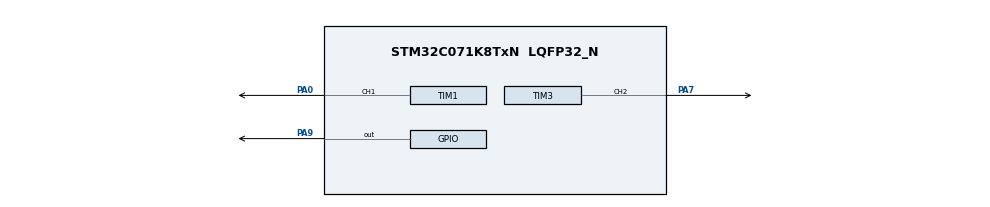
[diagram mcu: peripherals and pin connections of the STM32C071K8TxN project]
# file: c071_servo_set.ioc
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Mcu.Family=STM32C0
Mcu.Name=STM32C071K8TxN
Mcu.Package=LQFP32_N
PA0.Signal=S_TIM1_CH1
PA7.Signal=S_TIM3_CH2
PA9.PinState=GPIO_PIN_SET
PA9.Signal=GPIO_Output
ProjectManager.HeapSize=0x200
ProjectManager.StackSize=0x400
ProjectManager.TargetToolchain=STM32CubeIDE
RCC.ADCFreq_Value=48000000
RCC.AHBFreq_Value=48000000
RCC.CortexFreq_Value=48000000
RCC.EXTERNAL_CLOCK_VALUE=12288000
RCC.HCLKFreq_Value=48000000
RCC.HSE_VALUE=8000000
RCC.HSI48_VALUE=48000000
RCC.HSISYSCLKDivider=RCC_HSI_DIV1
RCC.HSI_VALUE=48000000
RCC.LSE_VALUE=32768
RCC.SYSCLKFreq_VALUE=48000000
SH.S_TIM1_CH1.0=TIM1_CH1,PWM Generation1 CH1
SH.S_TIM3_CH2.0=TIM3_CH2,PWM Generation2 CH2
TIM1.Channel-PWM\ Generation1\ CH1=TIM_CHANNEL_1
TIM3.Channel-PWM\ Generation2\ CH2=TIM_CHANNEL_2
TIM3.Prescaler=48
VP_TIM2_VS_ClockSourceINT.Mode=Internal
VP_TIM3_VS_ClockSourceINT.Mode=Internal
board=custom

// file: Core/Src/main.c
/* USER CODE BEGIN Header */
/**
  ******************************************************************************
  * @file           : main.c
  * @brief          : Main program body
  ******************************************************************************
  * @attention
  *
  * Copyright (c) 2026 STMicroelectronics.
  * All rights reserved.
  *
  * This software is licensed under terms that can be found in the LICENSE file
  * in the root directory of this software component.
  * If no LICENSE file comes with this software, it is provided AS-IS.
  *
  ******************************************************************************
  */
/* USER CODE END Header */
#include "main.h"

TIM_HandleTypeDef htim1;
TIM_HandleTypeDef htim2;
TIM_HandleTypeDef htim3;

void SystemClock_Config(void);
static void MX_GPIO_Init(void);
static void MX_TIM1_Init(void);
static void MX_TIM2_Init(void);
static void MX_TIM3_Init(void);

int main(void)
{

  /* MCU Configuration--------------------------------------------------------*/

  /* Reset of all peripherals, Initializes the Flash interface and the Systick. */
  HAL_Init();

  /* Configure the system clock */
  SystemClock_Config();

  /* Initialize all configured peripherals */
  MX_GPIO_Init();
  MX_TIM1_Init();
  MX_TIM2_Init();
  MX_TIM3_Init();
  /* USER CODE BEGIN 2 */
  HAL_TIM_Base_Start(&htim3);

  HAL_TIM_PWM_Start(&htim3, TIM_CHANNEL_2);

  HAL_Delay(100);
  /* USER CODE END 2 */

  /* Infinite loop */
  /* USER CODE BEGIN WHILE */
  while (1)
  {
// git commit attempt
	  servo_set_angle(0);
	  HAL_Delay(2000);
	  servo_set_angle(180);
	  HAL_Delay(2000);

    /* USER CODE END WHILE */

  }
}

void SystemClock_Config(void)
{
  RCC_OscInitTypeDef RCC_OscInitStruct = {0};
  RCC_ClkInitTypeDef RCC_ClkInitStruct = {0};

  __HAL_FLASH_SET_LATENCY(FLASH_LATENCY_1);

  /** Initializes the RCC Oscillators according to the specified parameters
  * in the RCC_OscInitTypeDef structure.
  */
  RCC_OscInitStruct.OscillatorType = RCC_OSCILLATORTYPE_HSI;
  RCC_OscInitStruct.HSIState = RCC_HSI_ON;
  RCC_OscInitStruct.HSIDiv = RCC_HSI_DIV1;
  RCC_OscInitStruct.HSICalibrationValue = RCC_HSICALIBRATION_DEFAULT;
  if (HAL_RCC_OscConfig(&RCC_OscInitStruct) != HAL_OK)
  {
    Error_Handler();
  }

  /** Initializes the CPU, AHB and APB buses clocks
  */
  RCC_ClkInitStruct.ClockType = RCC_CLOCKTYPE_HCLK|RCC_CLOCKTYPE_SYSCLK
                              |RCC_CLOCKTYPE_PCLK1;
  RCC_ClkInitStruct.SYSCLKSource = RCC_SYSCLKSOURCE_HSI;
  RCC_ClkInitStruct.SYSCLKDivider = RCC_SYSCLK_DIV1;
  RCC_ClkInitStruct.AHBCLKDivider = RCC_HCLK_DIV1;
  RCC_ClkInitStruct.APB1CLKDivider = RCC_APB1_DIV1;

  if (HAL_RCC_ClockConfig(&RCC_ClkInitStruct, FLASH_LATENCY_1) != HAL_OK)
  {
    Error_Handler();
  }
}

static void MX_TIM1_Init(void)
{

  TIM_MasterConfigTypeDef sMasterConfig = {0};
  TIM_OC_InitTypeDef sConfigOC = {0};
  TIM_BreakDeadTimeConfigTypeDef sBreakDeadTimeConfig = {0};

  htim1.Instance = TIM1;
  htim1.Init.Prescaler = 0;
  htim1.Init.CounterMode = TIM_COUNTERMODE_UP;
  htim1.Init.Period = 65535;
  htim1.Init.ClockDivision = TIM_CLOCKDIVISION_DIV1;
  htim1.Init.RepetitionCounter = 0;
  htim1.Init.AutoReloadPreload = TIM_AUTORELOAD_PRELOAD_DISABLE;
  if (HAL_TIM_PWM_Init(&htim1) != HAL_OK)
  {
    Error_Handler();
  }
  sMasterConfig.MasterOutputTrigger = TIM_TRGO_RESET;
  sMasterConfig.MasterOutputTrigger2 = TIM_TRGO2_RESET;
  sMasterConfig.MasterSlaveMode = TIM_MASTERSLAVEMODE_DISABLE;
  if (HAL_TIMEx_MasterConfigSynchronization(&htim1, &sMasterConfig) != HAL_OK)
  {
    Error_Handler();
  }
  sConfigOC.OCMode = TIM_OCMODE_PWM1;
  sConfigOC.Pulse = 0;
  sConfigOC.OCPolarity = TIM_OCPOLARITY_HIGH;
  sConfigOC.OCNPolarity = TIM_OCNPOLARITY_HIGH;
  sConfigOC.OCFastMode = TIM_OCFAST_DISABLE;
  sConfigOC.OCIdleState = TIM_OCIDLESTATE_RESET;
  sConfigOC.OCNIdleState = TIM_OCNIDLESTATE_RESET;
  if (HAL_TIM_PWM_ConfigChannel(&htim1, &sConfigOC, TIM_CHANNEL_1) != HAL_OK)
  {
    Error_Handler();
  }
  sBreakDeadTimeConfig.OffStateRunMode = TIM_OSSR_DISABLE;
  sBreakDeadTimeConfig.OffStateIDLEMode = TIM_OSSI_DISABLE;
  sBreakDeadTimeConfig.LockLevel = TIM_LOCKLEVEL_OFF;
  sBreakDeadTimeConfig.DeadTime = 0;
  sBreakDeadTimeConfig.BreakState = TIM_BREAK_DISABLE;
  sBreakDeadTimeConfig.BreakPolarity = TIM_BREAKPOLARITY_HIGH;
  sBreakDeadTimeConfig.BreakFilter = 0;
  sBreakDeadTimeConfig.BreakAFMode = TIM_BREAK_AFMODE_INPUT;
  sBreakDeadTimeConfig.Break2State = TIM_BREAK2_DISABLE;
  sBreakDeadTimeConfig.Break2Polarity = TIM_BREAK2POLARITY_HIGH;
  sBreakDeadTimeConfig.Break2Filter = 0;
  sBreakDeadTimeConfig.Break2AFMode = TIM_BREAK_AFMODE_INPUT;
  sBreakDeadTimeConfig.AutomaticOutput = TIM_AUTOMATICOUTPUT_DISABLE;
  if (HAL_TIMEx_ConfigBreakDeadTime(&htim1, &sBreakDeadTimeConfig) != HAL_OK)
  {
    Error_Handler();
  }
  HAL_TIM_MspPostInit(&htim1);

}

static void MX_TIM2_Init(void)
{

  TIM_ClockConfigTypeDef sClockSourceConfig = {0};
  TIM_MasterConfigTypeDef sMasterConfig = {0};

  htim2.Instance = TIM2;
  htim2.Init.Prescaler = 0;
  htim2.Init.CounterMode = TIM_COUNTERMODE_UP;
  htim2.Init.Period = 4294967295;
  htim2.Init.ClockDivision = TIM_CLOCKDIVISION_DIV1;
  htim2.Init.AutoReloadPreload = TIM_AUTORELOAD_PRELOAD_DISABLE;
  if (HAL_TIM_Base_Init(&htim2) != HAL_OK)
  {
    Error_Handler();
  }
  sClockSourceConfig.ClockSource = TIM_CLOCKSOURCE_INTERNAL;
  if (HAL_TIM_ConfigClockSource(&htim2, &sClockSourceConfig) != HAL_OK)
  {
    Error_Handler();
  }
  sMasterConfig.MasterOutputTrigger = TIM_TRGO_RESET;
  sMasterConfig.MasterSlaveMode = TIM_MASTERSLAVEMODE_DISABLE;
  if (HAL_TIMEx_MasterConfigSynchronization(&htim2, &sMasterConfig) != HAL_OK)
  {
    Error_Handler();
  }

}

static void MX_TIM3_Init(void)
{

  TIM_ClockConfigTypeDef sClockSourceConfig = {0};
  TIM_MasterConfigTypeDef sMasterConfig = {0};
  TIM_OC_InitTypeDef sConfigOC = {0};

  htim3.Instance = TIM3;
  htim3.Init.Prescaler = 48;
  htim3.Init.CounterMode = TIM_COUNTERMODE_UP;
  htim3.Init.Period = 65535;
  htim3.Init.ClockDivision = TIM_CLOCKDIVISION_DIV1;
  htim3.Init.AutoReloadPreload = TIM_AUTORELOAD_PRELOAD_DISABLE;
  if (HAL_TIM_Base_Init(&htim3) != HAL_OK)
  {
    Error_Handler();
  }
  sClockSourceConfig.ClockSource = TIM_CLOCKSOURCE_INTERNAL;
  if (HAL_TIM_ConfigClockSource(&htim3, &sClockSourceConfig) != HAL_OK)
  {
    Error_Handler();
  }
  if (HAL_TIM_PWM_Init(&htim3) != HAL_OK)
  {
    Error_Handler();
  }
  sMasterConfig.MasterOutputTrigger = TIM_TRGO_RESET;
  sMasterConfig.MasterSlaveMode = TIM_MASTERSLAVEMODE_DISABLE;
  if (HAL_TIMEx_MasterConfigSynchronization(&htim3, &sMasterConfig) != HAL_OK)
  {
    Error_Handler();
  }
  sConfigOC.OCMode = TIM_OCMODE_PWM1;
  sConfigOC.Pulse = 0;
  sConfigOC.OCPolarity = TIM_OCPOLARITY_HIGH;
  sConfigOC.OCFastMode = TIM_OCFAST_DISABLE;
  if (HAL_TIM_PWM_ConfigChannel(&htim3, &sConfigOC, TIM_CHANNEL_2) != HAL_OK)
  {
    Error_Handler();
  }
  HAL_TIM_MspPostInit(&htim3);

}

static void MX_GPIO_Init(void)
{
  GPIO_InitTypeDef GPIO_InitStruct = {0};

  /* GPIO Ports Clock Enable */
  __HAL_RCC_GPIOA_CLK_ENABLE();

  /*Configure GPIO pin Output Level */
  HAL_GPIO_WritePin(GPIOA, GPIO_PIN_9, GPIO_PIN_SET);

  /*Configure GPIO pin : PA9 */
  GPIO_InitStruct.Pin = GPIO_PIN_9;
  GPIO_InitStruct.Mode = GPIO_MODE_OUTPUT_PP;
  GPIO_InitStruct.Pull = GPIO_NOPULL;
  GPIO_InitStruct.Speed = GPIO_SPEED_FREQ_LOW;
  HAL_GPIO_Init(GPIOA, &GPIO_InitStruct);

}

/* USER CODE BEGIN 4 */

/******************************************************************************
 * Function    : servo_set_angle
 * Description : Moves the servo motor to the requested angle by changing
 *               the PWM pulse width.
 *
 * Parameter   : angle
 *               Servo angle in degrees (0° to 180°)
 *
 * Returns     : None
 *
 * Note:
 *   - Timer must be configured for a 20 ms (50 Hz) PWM period.
 *   - Timer resolution is assumed to be 1 µs per timer count.
 *   - Servo expects:
 *         0°   -> 500 µs pulse
 *         90°  -> 1500 µs pulse
 *         180° -> 2500 µs pulse
 ******************************************************************************/
void servo_set_angle(uint8_t angle)
{
    /*----------------------------------------------------------------------
     * Safety check
     * Prevent invalid angles greater than 180 degrees.
     * If angle is 200, 250, etc., it is limited to 180.
     *---------------------------------------------------------------------*/
    if (angle > 180U)
    {
        angle = 180U;
    }

    /*----------------------------------------------------------------------
     * Start PWM generation on TIM2 Channel 3.
     *
     * This enables the timer to generate the PWM signal.
     *
     * Normally this should be called only once during system initialization.
     * Calling it here repeatedly is not harmful but is unnecessary.
     *---------------------------------------------------------------------*/
    HAL_TIM_PWM_Start(&htim3, TIM_CHANNEL_2);

    /* Variable to store the timer compare value (pulse width). */
    uint16_t pulse;

    /*----------------------------------------------------------------------
     * Convert servo angle into pulse width.
     *
     * Formula:
     *
     *      Pulse = Minimum_Pulse +
     *              (Angle × Pulse_Range) / Maximum_Angle
     *
     * Where:
     *      Minimum_Pulse = 500 µs
     *      Pulse_Range   = 2000 µs
     *      Maximum_Angle = 180°
     *
     * Examples:
     *      Angle =   0°  ->  500 µs
     *      Angle =  90°  -> 1500 µs
     *      Angle = 180°  -> 2500 µs
     *---------------------------------------------------------------------*/
    pulse = 500U + ((uint32_t)angle * 2000U) / 180U;

    /*----------------------------------------------------------------------
     * Update the timer compare register.
     *
     * The timer hardware now generates:
     *
     *      HIGH for 'pulse' microseconds
     *      LOW  for the remaining time in the 20 ms period
     *
     * Example:
     *
     *      pulse = 1500
     *
     *      HIGH -----------------
     *            |               |
     *      ______|               |__________________
     *
     *         1.5 ms        Total period = 20 ms
     *
     * The servo measures this pulse width and rotates accordingly.
     *---------------------------------------------------------------------*/
    __HAL_TIM_SET_COMPARE(&htim3, TIM_CHANNEL_2, pulse);
}

void sweep(){
	  for (int i = 0 ;i <= 180 ; i++){
		  servo_set_angle(i);
		  HAL_Delay(20);
	  }
	  for (int i = 180 ;i >= 0 ; i--){
		  servo_set_angle(i);
		  HAL_Delay(20);
	  }
}

/* USER CODE END 4 */

void Error_Handler(void)
{
  __disable_irq();
  while (1)
  {
  }
}
